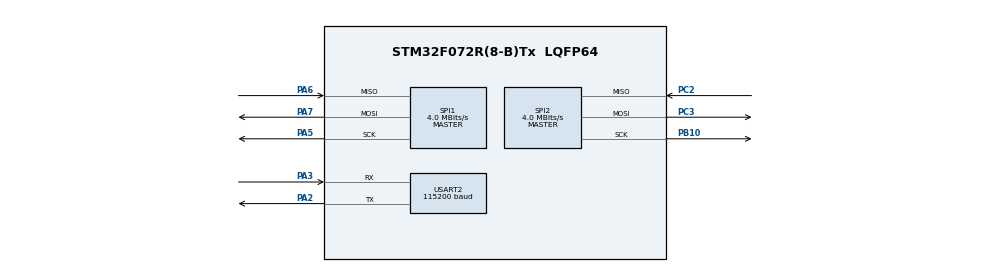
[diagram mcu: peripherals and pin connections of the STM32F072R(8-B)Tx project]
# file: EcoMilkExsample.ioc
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Mcu.Family=STM32F0
Mcu.Name=STM32F072R(8-B)Tx
Mcu.Package=LQFP64
PA2.Mode=Asynchronous
PA2.Signal=USART2_TX
PA3.Mode=Asynchronous
PA3.Signal=USART2_RX
PA5.Mode=Full_Duplex_Master
PA5.Signal=SPI1_SCK
PA6.Mode=Full_Duplex_Master
PA6.Signal=SPI1_MISO
PA7.Mode=Full_Duplex_Master
PA7.Signal=SPI1_MOSI
PB10.Mode=Full_Duplex_Master
PB10.Signal=SPI2_SCK
PC2.Mode=Full_Duplex_Master
PC2.Signal=SPI2_MISO
PC3.Mode=Full_Duplex_Master
PC3.Signal=SPI2_MOSI
ProjectManager.HeapSize=0x200
ProjectManager.StackSize=0x400
ProjectManager.TargetToolchain=EWARM V8.32
SPI1.CalculateBaudRate=4.0 MBits/s
SPI1.Direction=SPI_DIRECTION_2LINES
SPI1.Mode=SPI_MODE_MASTER
SPI1.VirtualType=VM_MASTER
SPI2.CalculateBaudRate=4.0 MBits/s
SPI2.Direction=SPI_DIRECTION_2LINES
SPI2.Mode=SPI_MODE_MASTER
SPI2.VirtualType=VM_MASTER
USART2.BaudRate=115200
USART2.VirtualMode-Asynchronous=VM_ASYNC
board=custom

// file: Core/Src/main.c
/* USER CODE BEGIN Header */
/**
  ******************************************************************************
  * @file           : main.c
  * @brief          : Main program body
  ******************************************************************************
  * @attention
  *
  * <h2><center>&copy; Copyright (c) 2021 STMicroelectronics.
  * All rights reserved.</center></h2>
  *
  * This software component is licensed by ST under BSD 3-Clause license,
  * the "License"; You may not use this file except in compliance with the
  * License. You may obtain a copy of the License at:
  *                        opensource.org/licenses/BSD-3-Clause
  *
  ******************************************************************************
  */
/* USER CODE END Header */
#include "main.h"
#include "stdio.h"
#include "stm32f0xx_hal_spi.h"

SPI_HandleTypeDef hspi1;
SPI_HandleTypeDef hspi2;

UART_HandleTypeDef huart2;

void SystemClock_Config(void);
static void MX_GPIO_Init(void);
static void MX_SPI1_Init(void);
static void MX_USART2_UART_Init(void);
static void MX_SPI2_Init(void);

int main(void)
{

  /* MCU Configuration--------------------------------------------------------*/

  /* Reset of all peripherals, Initializes the Flash interface and the Systick. */
  HAL_Init();

  /* Configure the system clock */
  SystemClock_Config();

  /* Initialize all configured peripherals */
  MX_GPIO_Init();
  MX_SPI1_Init();
  MX_USART2_UART_Init();
  MX_SPI2_Init();
  /* USER CODE BEGIN 2 */

    uint8_t rxdata[4] = {0x00, 0x00, 0x00, 0x00};
    uint8_t txdata[4] = {0x11, 0x22, 0x33, 0x44};
    HAL_StatusTypeDef status = HAL_ERROR;

    /* USER CODE END 2 */

  /* Infinite loop */
  while (1)
  {

    /* USER CODE BEGIN 3 */

    status = HAL_SPI_Transmit(&hspi1, txdata, 4, 100);
    status = HAL_SPI_Receive(&hspi1, rxdata, 4, 100);
    status = HAL_SPI_TransmitReceive(&hspi1, txdata, rxdata, 4, 500);

    if(status  != HAL_OK)
    //  printf("Hal SPI OK\n");
    //else
      printf("Hal SPI Error\n");

  }
  /* USER CODE END 3 */
}

void SystemClock_Config(void)
{
  RCC_OscInitTypeDef RCC_OscInitStruct = {0};
  RCC_ClkInitTypeDef RCC_ClkInitStruct = {0};
  RCC_PeriphCLKInitTypeDef PeriphClkInit = {0};

  /** Initializes the RCC Oscillators according to the specified parameters
  * in the RCC_OscInitTypeDef structure.
  */
  RCC_OscInitStruct.OscillatorType = RCC_OSCILLATORTYPE_HSI;
  RCC_OscInitStruct.HSIState = RCC_HSI_ON;
  RCC_OscInitStruct.HSICalibrationValue = RCC_HSICALIBRATION_DEFAULT;
  RCC_OscInitStruct.PLL.PLLState = RCC_PLL_NONE;
  if (HAL_RCC_OscConfig(&RCC_OscInitStruct) != HAL_OK)
  {
    Error_Handler();
  }
  /** Initializes the CPU, AHB and APB buses clocks
  */
  RCC_ClkInitStruct.ClockType = RCC_CLOCKTYPE_HCLK|RCC_CLOCKTYPE_SYSCLK
                              |RCC_CLOCKTYPE_PCLK1;
  RCC_ClkInitStruct.SYSCLKSource = RCC_SYSCLKSOURCE_HSI;
  RCC_ClkInitStruct.AHBCLKDivider = RCC_SYSCLK_DIV1;
  RCC_ClkInitStruct.APB1CLKDivider = RCC_HCLK_DIV1;

  if (HAL_RCC_ClockConfig(&RCC_ClkInitStruct, FLASH_LATENCY_0) != HAL_OK)
  {
    Error_Handler();
  }
  PeriphClkInit.PeriphClockSelection = RCC_PERIPHCLK_USART2;
  PeriphClkInit.Usart2ClockSelection = RCC_USART2CLKSOURCE_PCLK1;
  if (HAL_RCCEx_PeriphCLKConfig(&PeriphClkInit) != HAL_OK)
  {
    Error_Handler();
  }
}

static void MX_SPI1_Init(void)
{

  /* SPI1 parameter configuration*/
  hspi1.Instance = SPI1;
  hspi1.Init.Mode = SPI_MODE_MASTER;
  hspi1.Init.Direction = SPI_DIRECTION_2LINES;
  hspi1.Init.DataSize = SPI_DATASIZE_4BIT;
  hspi1.Init.CLKPolarity = SPI_POLARITY_LOW;
  hspi1.Init.CLKPhase = SPI_PHASE_1EDGE;
  hspi1.Init.NSS = SPI_NSS_SOFT;
  hspi1.Init.BaudRatePrescaler = SPI_BAUDRATEPRESCALER_2;
  hspi1.Init.FirstBit = SPI_FIRSTBIT_MSB;
  hspi1.Init.TIMode = SPI_TIMODE_DISABLE;
  hspi1.Init.CRCCalculation = SPI_CRCCALCULATION_DISABLE;
  hspi1.Init.CRCPolynomial = 7;
  hspi1.Init.CRCLength = SPI_CRC_LENGTH_DATASIZE;
  hspi1.Init.NSSPMode = SPI_NSS_PULSE_ENABLE;
  if (HAL_SPI_Init(&hspi1) != HAL_OK)
  {
    Error_Handler();
  }

}

static void MX_SPI2_Init(void)
{

  /* SPI2 parameter configuration*/
  hspi2.Instance = SPI2;
  hspi2.Init.Mode = SPI_MODE_MASTER;
  hspi2.Init.Direction = SPI_DIRECTION_2LINES;
  hspi2.Init.DataSize = SPI_DATASIZE_4BIT;
  hspi2.Init.CLKPolarity = SPI_POLARITY_LOW;
  hspi2.Init.CLKPhase = SPI_PHASE_1EDGE;
  hspi2.Init.NSS = SPI_NSS_SOFT;
  hspi2.Init.BaudRatePrescaler = SPI_BAUDRATEPRESCALER_2;
  hspi2.Init.FirstBit = SPI_FIRSTBIT_MSB;
  hspi2.Init.TIMode = SPI_TIMODE_DISABLE;
  hspi2.Init.CRCCalculation = SPI_CRCCALCULATION_DISABLE;
  hspi2.Init.CRCPolynomial = 7;
  hspi2.Init.CRCLength = SPI_CRC_LENGTH_DATASIZE;
  hspi2.Init.NSSPMode = SPI_NSS_PULSE_ENABLE;
  if (HAL_SPI_Init(&hspi2) != HAL_OK)
  {
    Error_Handler();
  }

}

static void MX_USART2_UART_Init(void)
{

  huart2.Instance = USART2;
  huart2.Init.BaudRate = 115200;
  huart2.Init.WordLength = UART_WORDLENGTH_8B;
  huart2.Init.StopBits = UART_STOPBITS_1;
  huart2.Init.Parity = UART_PARITY_NONE;
  huart2.Init.Mode = UART_MODE_TX_RX;
  huart2.Init.HwFlowCtl = UART_HWCONTROL_NONE;
  huart2.Init.OverSampling = UART_OVERSAMPLING_16;
  huart2.Init.OneBitSampling = UART_ONE_BIT_SAMPLE_DISABLE;
  huart2.AdvancedInit.AdvFeatureInit = UART_ADVFEATURE_NO_INIT;
  if (HAL_UART_Init(&huart2) != HAL_OK)
  {
    Error_Handler();
  }

}

static void MX_GPIO_Init(void)
{

  /* GPIO Ports Clock Enable */
  __HAL_RCC_GPIOC_CLK_ENABLE();
  __HAL_RCC_GPIOA_CLK_ENABLE();
  __HAL_RCC_GPIOB_CLK_ENABLE();

}

void Error_Handler(void)
{
  __disable_irq();
  while (1)
  {
  }
}

/************************ (C) COPYRIGHT STMicroelectronics *****END OF FILE****/
